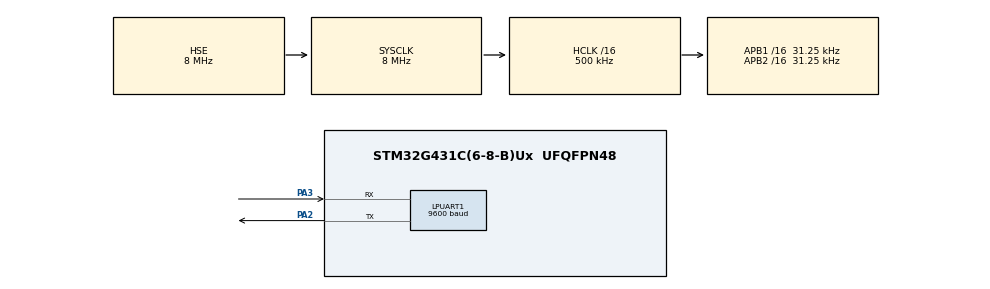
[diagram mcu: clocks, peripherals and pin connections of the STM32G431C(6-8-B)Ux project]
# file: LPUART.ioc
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LPTIM1.ClockPrescaler=LPTIM_PRESCALER_DIV128
LPUART1.BaudRate=9600
Mcu.Family=STM32G4
Mcu.Name=STM32G431C(6-8-B)Ux
Mcu.Package=UFQFPN48
NVIC.LPTIM1_IRQn=true\:0\:0\:false\:false\:true\:true\:true\:true
NVIC.PriorityGroup=NVIC_PRIORITYGROUP_4
PA13.Mode=Trace_Asynchronous_SW
PA13.Signal=SYS_JTMS-SWDIO
PA14.Mode=Trace_Asynchronous_SW
PA14.Signal=SYS_JTCK-SWCLK
PA2.Mode=Asynchronous
PA2.Signal=LPUART1_TX
PA3.Mode=Asynchronous
PA3.Signal=LPUART1_RX
PB3.Mode=Trace_Asynchronous_SW
PB3.Signal=SYS_JTDO-SWO
PF0-OSC_IN.Mode=HSE-External-Oscillator
PF0-OSC_IN.Signal=RCC_OSC_IN
PF1-OSC_OUT.Mode=HSE-External-Oscillator
PF1-OSC_OUT.Signal=RCC_OSC_OUT
ProjectManager.HeapSize=0x200
ProjectManager.StackSize=0x400
ProjectManager.TargetToolchain=STM32CubeIDE
RCC.ADC12Freq_Value=8000000
RCC.AHBCLKDivider=RCC_SYSCLK_DIV16
RCC.AHBFreq_Value=500000
RCC.APB1CLKDivider=RCC_HCLK_DIV16
RCC.APB1Freq_Value=31250
RCC.APB1TimFreq_Value=62500
RCC.APB2CLKDivider=RCC_HCLK_DIV16
RCC.APB2Freq_Value=31250
RCC.APB2TimFreq_Value=62500
RCC.CortexFreq_Value=62500
RCC.Cortex_Div=SYSTICK_CLKSOURCE_HCLK_DIV8
RCC.EXTERNAL_CLOCK_VALUE=12288000
RCC.HCLKFreq_Value=500000
RCC.HSE_VALUE=8000000
RCC.HSI48_VALUE=48000000
RCC.HSI_VALUE=16000000
RCC.SYSCLKFreq_VALUE=8000000
RCC.SYSCLKSource=RCC_SYSCLKSOURCE_HSE
RCC.USBFreq_Value=64000000
RCC.VCOOutputFreq_Value=128000000
VP_LPTIM1_VS_LPTIM_counterModeInternalClock.Mode=Counts__internal_clock_event_00
VP_SYS_VS_DBSignals.Mode=DisableDeadBatterySignals
board=custom

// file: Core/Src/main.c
/* USER CODE BEGIN Header */
/**
  ******************************************************************************
  * @file           : main.c
  * @brief          : Main program body
  ******************************************************************************
  * @attention
  *
  * Copyright (c) 2025 STMicroelectronics.
  * All rights reserved.
  *
  * This software is licensed under terms that can be found in the LICENSE file
  * in the root directory of this software component.
  * If no LICENSE file comes with this software, it is provided AS-IS.
  *
  ******************************************************************************
  */
/* USER CODE END Header */
#include "main.h"

/* USER CODE BEGIN Includes */
#include "console.h"
/* USER CODE END Includes */

LPTIM_HandleTypeDef hlptim1;

UART_HandleTypeDef hlpuart1;

void SystemClock_Config(void);
static void MX_GPIO_Init(void);
static void MX_LPUART1_UART_Init(void);
static void MX_LPTIM1_Init(void);

/* USER CODE BEGIN 0 */

void HAL_LPTIM_AutoReloadMatchCallback(LPTIM_HandleTypeDef *hlptim) {
	printf("LPTIM\r\n");
}

/* USER CODE END 0 */

int main(void)
{

  /* MCU Configuration--------------------------------------------------------*/

  /* Reset of all peripherals, Initializes the Flash interface and the Systick. */
  HAL_Init();

  /* Configure the system clock */
  SystemClock_Config();

  /* Initialize all configured peripherals */
  MX_GPIO_Init();
  MX_LPUART1_UART_Init();
  MX_LPTIM1_Init();
  /* USER CODE BEGIN 2 */

  uint16_t Period = 3 * (31250 / 127);  // Every 3 sec; 31250 - LPTIM clocking; 127 - Prescaler
  HAL_LPTIM_Counter_Start_IT(&hlptim1, Period);

  printf("\r\nStart\r\n");

  /* USER CODE END 2 */

  /* Infinite loop */
  while (1)
  {

  }
}

void SystemClock_Config(void)
{
  RCC_OscInitTypeDef RCC_OscInitStruct = {0};
  RCC_ClkInitTypeDef RCC_ClkInitStruct = {0};

  /** Configure the main internal regulator output voltage
  */
  HAL_PWREx_ControlVoltageScaling(PWR_REGULATOR_VOLTAGE_SCALE1);

  /** Initializes the RCC Oscillators according to the specified parameters
  * in the RCC_OscInitTypeDef structure.
  */
  RCC_OscInitStruct.OscillatorType = RCC_OSCILLATORTYPE_HSE;
  RCC_OscInitStruct.HSEState = RCC_HSE_ON;
  RCC_OscInitStruct.PLL.PLLState = RCC_PLL_NONE;
  if (HAL_RCC_OscConfig(&RCC_OscInitStruct) != HAL_OK)
  {
    Error_Handler();
  }

  /** Initializes the CPU, AHB and APB buses clocks
  */
  RCC_ClkInitStruct.ClockType = RCC_CLOCKTYPE_HCLK|RCC_CLOCKTYPE_SYSCLK
                              |RCC_CLOCKTYPE_PCLK1|RCC_CLOCKTYPE_PCLK2;
  RCC_ClkInitStruct.SYSCLKSource = RCC_SYSCLKSOURCE_HSE;
  RCC_ClkInitStruct.AHBCLKDivider = RCC_SYSCLK_DIV16;
  RCC_ClkInitStruct.APB1CLKDivider = RCC_HCLK_DIV16;
  RCC_ClkInitStruct.APB2CLKDivider = RCC_HCLK_DIV16;

  if (HAL_RCC_ClockConfig(&RCC_ClkInitStruct, FLASH_LATENCY_0) != HAL_OK)
  {
    Error_Handler();
  }
}

static void MX_LPTIM1_Init(void)
{

  hlptim1.Instance = LPTIM1;
  hlptim1.Init.Clock.Source = LPTIM_CLOCKSOURCE_APBCLOCK_LPOSC;
  hlptim1.Init.Clock.Prescaler = LPTIM_PRESCALER_DIV128;
  hlptim1.Init.Trigger.Source = LPTIM_TRIGSOURCE_SOFTWARE;
  hlptim1.Init.OutputPolarity = LPTIM_OUTPUTPOLARITY_HIGH;
  hlptim1.Init.UpdateMode = LPTIM_UPDATE_IMMEDIATE;
  hlptim1.Init.CounterSource = LPTIM_COUNTERSOURCE_INTERNAL;
  hlptim1.Init.Input1Source = LPTIM_INPUT1SOURCE_GPIO;
  hlptim1.Init.Input2Source = LPTIM_INPUT2SOURCE_GPIO;
  if (HAL_LPTIM_Init(&hlptim1) != HAL_OK)
  {
    Error_Handler();
  }

}

static void MX_LPUART1_UART_Init(void)
{

  hlpuart1.Instance = LPUART1;
  hlpuart1.Init.BaudRate = 9600;
  hlpuart1.Init.WordLength = UART_WORDLENGTH_8B;
  hlpuart1.Init.StopBits = UART_STOPBITS_1;
  hlpuart1.Init.Parity = UART_PARITY_NONE;
  hlpuart1.Init.Mode = UART_MODE_TX_RX;
  hlpuart1.Init.HwFlowCtl = UART_HWCONTROL_NONE;
  hlpuart1.Init.OneBitSampling = UART_ONE_BIT_SAMPLE_DISABLE;
  hlpuart1.Init.ClockPrescaler = UART_PRESCALER_DIV1;
  hlpuart1.AdvancedInit.AdvFeatureInit = UART_ADVFEATURE_NO_INIT;
  if (HAL_UART_Init(&hlpuart1) != HAL_OK)
  {
    Error_Handler();
  }
  if (HAL_UARTEx_SetTxFifoThreshold(&hlpuart1, UART_TXFIFO_THRESHOLD_1_8) != HAL_OK)
  {
    Error_Handler();
  }
  if (HAL_UARTEx_SetRxFifoThreshold(&hlpuart1, UART_RXFIFO_THRESHOLD_1_8) != HAL_OK)
  {
    Error_Handler();
  }
  if (HAL_UARTEx_DisableFifoMode(&hlpuart1) != HAL_OK)
  {
    Error_Handler();
  }

}

static void MX_GPIO_Init(void)
{

  /* GPIO Ports Clock Enable */
  __HAL_RCC_GPIOF_CLK_ENABLE();
  __HAL_RCC_GPIOA_CLK_ENABLE();
  __HAL_RCC_GPIOB_CLK_ENABLE();

}

void Error_Handler(void)
{
  __disable_irq();
  while (1)
  {
  }
}
